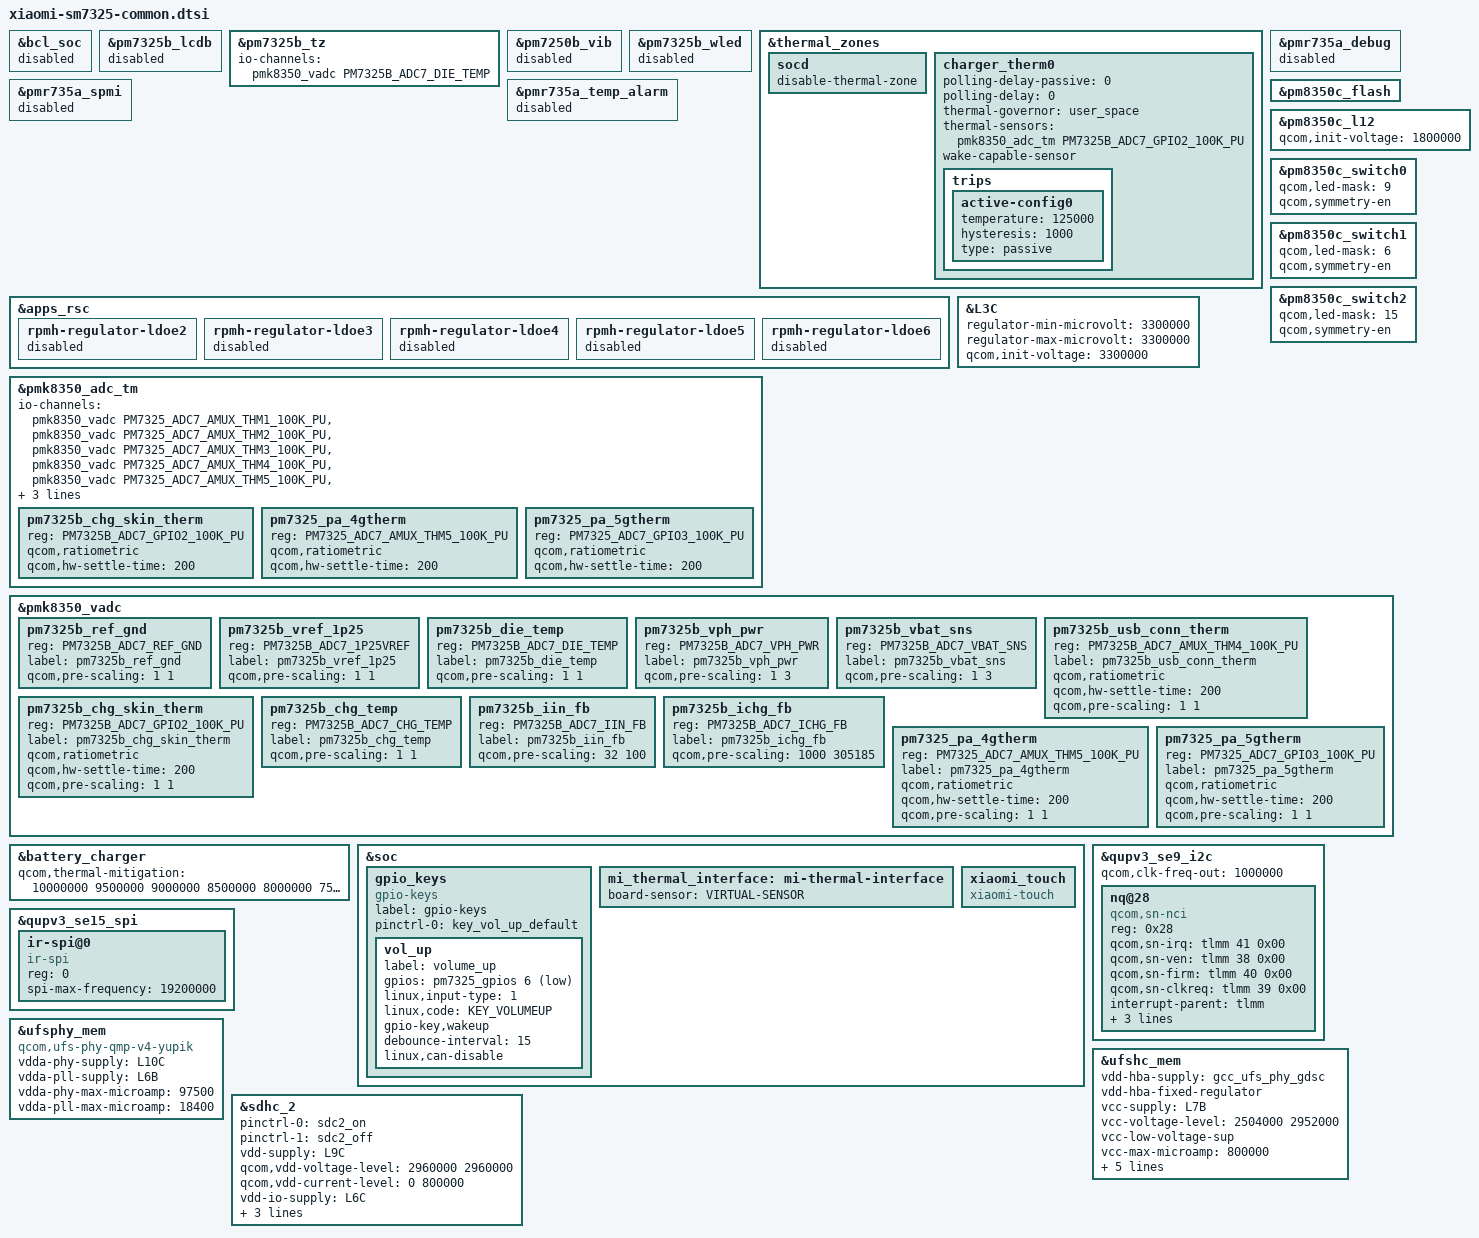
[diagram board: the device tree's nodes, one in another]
#include <dt-bindings/gpio/gpio.h>
#include <dt-bindings/regulator/qcom,rpmh-regulator-levels.h>
#include <dt-bindings/iio/qcom,spmi-adc7-pm7325b.h>
#include "yupik-pmic-overlay.dtsi"
#include "pm7325b.dtsi"
#include "yupik-thermal-overlay.dtsi"

/*
 * PM7325B devices not used by Xiaomi SM7325 platform
 */
&bcl_soc {
	status = "disabled";
};

&pm7325b_lcdb {
	status = "disabled";
};

&pm7325b_tz {
	io-channels = <&pmk8350_vadc PM7325B_ADC7_DIE_TEMP>;
	io-channel-names = "thermal";
};

&pm7250b_vib {
	status = "disabled";
};

&pm7325b_wled {
	status = "disabled";
};

&thermal_zones {
	socd {
		disable-thermal-zone;
	};
};

/*
 * PMR735a specific diff for xiaomi sm7325 platform
 */
&pmr735a_debug {
	status = "disabled";
};

&pmr735a_spmi {
	status = "disabled";
};

&pmr735a_temp_alarm {
	status = "disabled";
};

&apps_rsc {
	rpmh-regulator-ldoe2 {
		status = "disabled";
	};

	rpmh-regulator-ldoe3 {
		status = "disabled";
	};

	rpmh-regulator-ldoe4 {
		status = "disabled";
	};

	rpmh-regulator-ldoe5 {
		status = "disabled";
	};

	rpmh-regulator-ldoe6 {
		status = "disabled";
	};
};

/*
 * PM8350C devices specific diff for Xiaomi SM7325 platform
 */
&L3C {
	regulator-min-microvolt = <3300000>;
	regulator-max-microvolt = <3300000>;
	qcom,init-voltage = <3300000>;
};

&pm8350c_flash {
	status = "ok";
};

&pm8350c_l12 {
	qcom,init-voltage = <1800000>;
};

&pm8350c_switch0 {
	qcom,led-mask = <9>; /* Channels 1 & 4 */
	qcom,symmetry-en;
};

&pm8350c_switch1 {
	qcom,led-mask = <6>; /* Channels 2 & 3 */
	qcom,symmetry-en;
};

&pm8350c_switch2 {
	qcom,led-mask = <15>; /* All Channels */
	qcom,symmetry-en;
};

/*
 * PMK8350 specific diff for Xiaomi SM7325 platform
 */
&pmk8350_adc_tm {
	io-channels = <&pmk8350_vadc PM7325_ADC7_AMUX_THM1_100K_PU>,
				  <&pmk8350_vadc PM7325_ADC7_AMUX_THM2_100K_PU>,
				  <&pmk8350_vadc PM7325_ADC7_AMUX_THM3_100K_PU>,
				  <&pmk8350_vadc PM7325_ADC7_AMUX_THM4_100K_PU>,
				  <&pmk8350_vadc PM7325_ADC7_AMUX_THM5_100K_PU>,
				  <&pmk8350_vadc PMK8350_ADC7_AMUX_THM1_100K_PU>,
				  <&pmk8350_vadc PM7325B_ADC7_GPIO2_100K_PU>,
				  <&pmk8350_vadc PM7325_ADC7_GPIO3_100K_PU>;

	pm7325b_chg_skin_therm {
		reg = <PM7325B_ADC7_GPIO2_100K_PU>;
		qcom,ratiometric;
		qcom,hw-settle-time = <200>;
	};

	pm7325_pa_4gtherm {
		reg = <PM7325_ADC7_AMUX_THM5_100K_PU>;
		qcom,ratiometric;
		qcom,hw-settle-time = <200>;
	};

	pm7325_pa_5gtherm {
		reg = <PM7325_ADC7_GPIO3_100K_PU>;
		qcom,ratiometric;
		qcom,hw-settle-time = <200>;
	};
};

&pmk8350_vadc {
	/delete-node/ pmr735a_ref_gnd;
	/delete-node/ pmr735a_vref_1p25;
	/delete-node/ pmr735a_die_temp;

	pm7325b_ref_gnd {
		reg = <PM7325B_ADC7_REF_GND>;
		label = "pm7325b_ref_gnd";
		qcom,pre-scaling = <1 1>;
	};

	pm7325b_vref_1p25 {
		reg = <PM7325B_ADC7_1P25VREF>;
		label = "pm7325b_vref_1p25";
		qcom,pre-scaling = <1 1>;
	};

	pm7325b_die_temp {
		reg = <PM7325B_ADC7_DIE_TEMP>;
		label = "pm7325b_die_temp";
		qcom,pre-scaling = <1 1>;
	};

	pm7325b_vph_pwr {
		reg = <PM7325B_ADC7_VPH_PWR>;
		label = "pm7325b_vph_pwr";
		qcom,pre-scaling = <1 3>;
	};

	pm7325b_vbat_sns {
		reg = <PM7325B_ADC7_VBAT_SNS>;
		label = "pm7325b_vbat_sns";
		qcom,pre-scaling = <1 3>;
	};

	pm7325b_usb_conn_therm {
		reg = <PM7325B_ADC7_AMUX_THM4_100K_PU>;
		label = "pm7325b_usb_conn_therm";
		qcom,ratiometric;
		qcom,hw-settle-time = <200>;
		qcom,pre-scaling = <1 1>;
	};

	pm7325b_chg_skin_therm {
		reg = <PM7325B_ADC7_GPIO2_100K_PU>;
		label = "pm7325b_chg_skin_therm";
		qcom,ratiometric;
		qcom,hw-settle-time = <200>;
		qcom,pre-scaling = <1 1>;
	};

	pm7325b_chg_temp {
		reg = <PM7325B_ADC7_CHG_TEMP>;
		label = "pm7325b_chg_temp";
		qcom,pre-scaling = <1 1>;
	};

	pm7325b_iin_fb {
		reg = <PM7325B_ADC7_IIN_FB>;
		label = "pm7325b_iin_fb";
		qcom,pre-scaling = <32 100>;
	};

	pm7325b_ichg_fb {
		reg = <PM7325B_ADC7_ICHG_FB>;
		label = "pm7325b_ichg_fb";
		qcom,pre-scaling = <1000 305185>;
	};

	pm7325_pa_4gtherm {
		reg = <PM7325_ADC7_AMUX_THM5_100K_PU>;
		label = "pm7325_pa_4gtherm";
		qcom,ratiometric;
		qcom,hw-settle-time = <200>;
		qcom,pre-scaling = <1 1>;
	};

	pm7325_pa_5gtherm {
		reg = <PM7325_ADC7_GPIO3_100K_PU>;
		label = "pm7325_pa_5gtherm";
		qcom,ratiometric;
		qcom,hw-settle-time = <200>;
		qcom,pre-scaling = <1 1>;
	};
};

&thermal_zones {
	charger_therm0 {
		polling-delay-passive = <0>;
		polling-delay = <0>;
		thermal-governor = "user_space";
		thermal-sensors = <&pmk8350_adc_tm PM7325B_ADC7_GPIO2_100K_PU>;
		wake-capable-sensor;

		trips {
			active-config0 {
				temperature = <125000>;
				hysteresis = <1000>;
				type = "passive";
			};
		};
	};
};

&battery_charger {
	qcom,thermal-mitigation = <10000000 9500000 9000000 8500000 8000000
							7500000 7000000 6500000 6000000 5500000
							5000000 4500000 4000000 3500000 3000000
							2500000 2000000 1500000 1000000 500000>;
};

&soc {
	gpio_keys {
		compatible = "gpio-keys";
		label = "gpio-keys";

		pinctrl-names = "default";
		pinctrl-0 = <&key_vol_up_default>;

		vol_up {
			label = "volume_up";
			gpios = <&pm7325_gpios 6 GPIO_ACTIVE_LOW>;
			linux,input-type = <1>;
			linux,code = <KEY_VOLUMEUP>;
			gpio-key,wakeup;
			debounce-interval = <15>;
			linux,can-disable;
		};
	};

	mi_thermal_interface: mi-thermal-interface {
		board-sensor = "VIRTUAL-SENSOR";
	};

	xiaomi_touch {
		compatible = "xiaomi-touch";
		status = "ok";
	};
};

&qupv3_se9_i2c {
	status = "ok";
	qcom,clk-freq-out = <1000000>;
	#address-cells = <1>;
	#size-cells = <0>;

	nq@28 {
		compatible = "qcom,sn-nci";
		reg = <0x28>;
		qcom,sn-irq = <&tlmm 41 0x00>;
		qcom,sn-ven = <&tlmm 38 0x00>;
		qcom,sn-firm = <&tlmm 40 0x00>;
		qcom,sn-clkreq = <&tlmm 39 0x00>;
		interrupt-parent = <&tlmm>;
		interrupts = <41 0>;
		interrupt-names = "nfc_irq";
		pinctrl-names = "nfc_active", "nfc_suspend";
		pinctrl-0 = <&nfc_int_active &nfc_enable_active>;
		pinctrl-1 = <&nfc_int_suspend &nfc_enable_suspend>;
	};
};


&qupv3_se15_spi {
	status = "ok";
	ir-spi@0 {
		compatible = "ir-spi";
		reg = <0>;
		spi-max-frequency = <19200000>;
		status = "ok";
	};
};

&ufsphy_mem {
	compatible = "qcom,ufs-phy-qmp-v4-yupik";

	vdda-phy-supply = <&L10C>;
	vdda-pll-supply = <&L6B>;
	vdda-phy-max-microamp = <97500>;
	vdda-pll-max-microamp = <18400>;

	status = "ok";
};

&ufshc_mem {
	vdd-hba-supply = <&gcc_ufs_phy_gdsc>;
	vdd-hba-fixed-regulator;

	vcc-supply = <&L7B>;
	vcc-voltage-level = <2504000 2952000>;
	vcc-low-voltage-sup;
	vcc-max-microamp = <800000>;

	/*
	 * Yupik target supports both UFS2.2 & UFS3.1, here
	 * vccq2 is supplied via eLDO, and that is controlled via
	 * L9B which supports a max voltage of 1.2V, but eLDO would
	 * supply 1.8V. and same L9B acts as vccq voltage for UFS3.1
	 * devices.
	 * Here L9B can max support for 1.2V but UFS GKI driver code
	 * votes for 1.8V, which is leading to failure from pmic
	 * regulator.
	 *
	 * Now since vccq and control of eLDO are common that is L9B
	 * we can use vccq vote as control of eLDO for vccq2.
	 * Hence vccq entries shall be used for both type of UFS
	 * devices only. And vccq entries should not be changed/removed
	 * for any design alteration.
	 */
	vccq-supply = <&L9B>;
	vccq-max-microamp = <900000>;
	vccq-min-microamp = <10000>;

	qcom,vddp-ref-clk-supply = <&L9B>;
	qcom,vddp-ref-clk-max-microamp = <100>;

	status = "ok";
};

&sdhc_2 {
	pinctrl-names = "default", "sleep";
	pinctrl-0 = <&sdc2_on>;
	pinctrl-1 = <&sdc2_off>;

	vdd-supply = <&L9C>;
	qcom,vdd-voltage-level = <2960000 2960000>;
	qcom,vdd-current-level = <0 800000>;

	vdd-io-supply = <&L6C>;
	qcom,vdd-io-voltage-level = <1800000 2960000>;
	qcom,vdd-io-current-level = <0 22000>;

	cd-gpios = <&tlmm 91 GPIO_ACTIVE_HIGH>;

	status = "ok";
};
